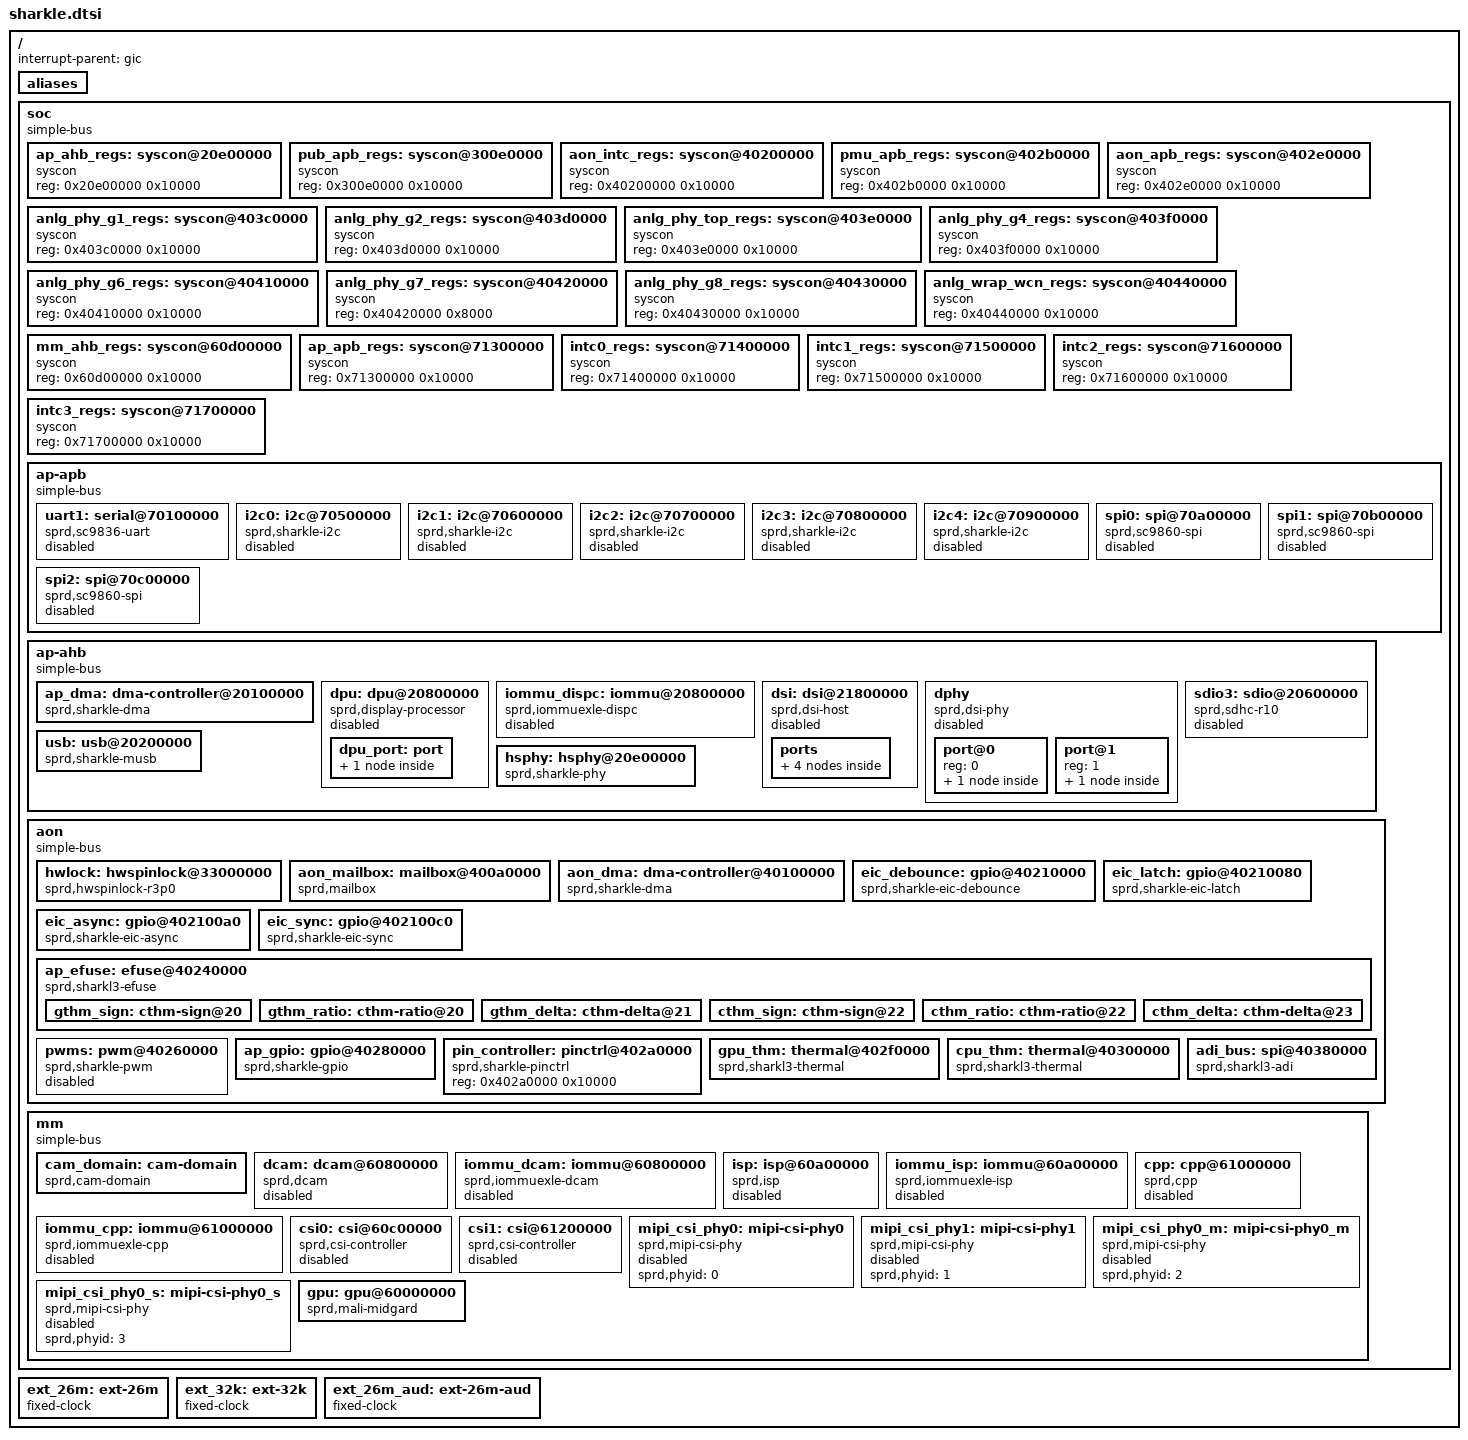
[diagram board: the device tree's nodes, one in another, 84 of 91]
/*
 * Spreadtrum sharkle platform DTS file
 *
 * Copyright (C) 2019, Spreadtrum Communications Inc.
 *
 * This file is licensed under a dual GPLv2 or X11 license.
 */
#include <dt-bindings/interrupt-controller/arm-gic.h>
#include <dt-bindings/soc/sprd,sharkle-regs.h>
#include <dt-bindings/soc/sprd,sharkle-mask.h>

/ {
	interrupt-parent = <&gic>;
	#address-cells = <1>;
	#size-cells = <1>;

	aliases {
		serial1 = &uart1;
		i2c0 = &i2c0;
		i2c1 = &i2c1;
		i2c2 = &i2c2;
		i2c3 = &i2c3;
		i2c4 = &i2c4;
		spi0 = &spi0;
		spi1 = &spi1;
		spi2 = &spi2;
	};

	soc: soc {
		compatible = "simple-bus";
		#address-cells = <1>;
		#size-cells = <1>;
		ranges;

		ap_ahb_regs: syscon@20e00000 {
			compatible = "syscon";
			#syscon-cells = <2>;
			reg = <0x20e00000 0x10000>;
		};

		pub_apb_regs: syscon@300e0000 {
			compatible = "syscon";
			#syscon-cells = <2>;
			reg = <0x300e0000 0x10000>;
		};

		aon_intc_regs: syscon@40200000 {
			compatible = "syscon";
			#syscon-cells = <2>;
			reg = <0x40200000 0x10000>;
		};

		pmu_apb_regs: syscon@402b0000 {
			compatible = "syscon";
			#syscon-cells = <2>;
			reg = <0x402b0000 0x10000>;
		};

		aon_apb_regs: syscon@402e0000 {
			compatible = "syscon";
			#syscon-cells = <2>;
			reg = <0x402e0000 0x10000>;
		};

		anlg_phy_g1_regs: syscon@403c0000 {
			compatible = "syscon";
			#syscon-cells = <2>;
			reg = <0x403c0000 0x10000>;
		};

		anlg_phy_g2_regs: syscon@403d0000 {
			compatible = "syscon";
			#syscon-cells = <2>;
			reg = <0x403d0000 0x10000>;
		};

		anlg_phy_top_regs: syscon@403e0000 {
			compatible = "syscon";
			#syscon-cells = <2>;
			reg = <0x403e0000 0x10000>;
		};

		anlg_phy_g4_regs: syscon@403f0000 {
			compatible = "syscon";
			#syscon-cells = <2>;
			reg = <0x403f0000 0x10000>;
		};

		anlg_phy_g6_regs: syscon@40410000 {
			compatible = "syscon";
			#syscon-cells = <2>;
			reg = <0x40410000 0x10000>;
		};

		anlg_phy_g7_regs: syscon@40420000 {
			compatible = "syscon";
			#syscon-cells = <2>;
			reg = <0x40420000 0x8000>;
		};

		anlg_phy_g8_regs: syscon@40430000 {
			compatible = "syscon";
			#syscon-cells = <2>;
			reg = <0x40430000 0x10000>;
		};

		anlg_wrap_wcn_regs: syscon@40440000 {
			compatible = "syscon";
			#syscon-cells = <2>;
			reg = <0x40440000 0x10000>;
		};

		mm_ahb_regs: syscon@60d00000 {
			compatible = "syscon";
			#syscon-cells = <2>;
			reg = <0x60d00000 0x10000>;
		};

		ap_apb_regs: syscon@71300000 {
			compatible = "syscon";
			#syscon-cells = <2>;
			reg = <0x71300000 0x10000>;
		};

		intc0_regs: syscon@71400000 {
			compatible = "syscon";
			#syscon-cells = <2>;
			reg = <0x71400000 0x10000>;
		};

		intc1_regs: syscon@71500000 {
			compatible = "syscon";
			#syscon-cells = <2>;
			reg = <0x71500000 0x10000>;
		};

		intc2_regs: syscon@71600000 {
			compatible = "syscon";
			#syscon-cells = <2>;
			reg = <0x71600000 0x10000>;
		};

		intc3_regs: syscon@71700000 {
			compatible = "syscon";
			#syscon-cells = <2>;
			reg = <0x71700000 0x10000>;
		};

		ap-apb {
			compatible = "simple-bus";
			#address-cells = <1>;
			#size-cells = <1>;
			ranges;

			uart1: serial@70100000 {
				compatible = "sprd,sc9836-uart";
				reg = <0x70100000 0x100>;
				interrupts = <GIC_SPI 3 IRQ_TYPE_LEVEL_HIGH>;
				status = "disabled";
			};

			i2c0: i2c@70500000 {
				compatible = "sprd,sharkle-i2c";
				reg = <0x70500000 0x100>;
				interrupts = <GIC_SPI 11 IRQ_TYPE_LEVEL_HIGH>;
				clock-frequency = <100000>;
				#address-cells = <1>;
				#size-cells = <0>;
				status = "disabled";
			};

			i2c1: i2c@70600000 {
				compatible = "sprd,sharkle-i2c";
				reg = <0x70600000 0x100>;
				interrupts = <GIC_SPI 12 IRQ_TYPE_LEVEL_HIGH>;
				clock-frequency = <100000>;
				#address-cells = <1>;
				#size-cells = <0>;
				status = "disabled";
			};

			i2c2: i2c@70700000 {
				compatible = "sprd,sharkle-i2c";
				reg = <0x70700000 0x100>;
				interrupts = <GIC_SPI 13 IRQ_TYPE_LEVEL_HIGH>;
				clock-frequency = <100000>;
				#address-cells = <1>;
				#size-cells = <0>;
				status = "disabled";
			};

			i2c3: i2c@70800000 {
				compatible = "sprd,sharkle-i2c";
				reg = <0x70800000 0x100>;
				interrupts = <GIC_SPI 14 IRQ_TYPE_LEVEL_HIGH>;
				clock-frequency = <400000>;
				#address-cells = <1>;
				#size-cells = <0>;
				status = "disabled";
			};

			i2c4: i2c@70900000 {
				compatible = "sprd,sharkle-i2c";
				reg = <0x70900000 0x100>;
				interrupts = <GIC_SPI 15 IRQ_TYPE_LEVEL_HIGH>;
				clock-frequency = <100000>;
				#address-cells = <1>;
				#size-cells = <0>;
				status = "disabled";
			};

			spi0: spi@70a00000 {
				compatible = "sprd,sc9860-spi",
					"sprd,sharkle-spi";
				reg = <0x70a00000 0x1000>;
				interrupts = <GIC_SPI 7 IRQ_TYPE_LEVEL_HIGH>;
				#address-cells = <1>;
				#size-cells = <0>;
				status = "disabled";
			};

			spi1: spi@70b00000 {
				compatible = "sprd,sc9860-spi",
					"sprd,sharkle-spi";
				reg = <0x70b00000 0x1000>;
				interrupts = <GIC_SPI 8 IRQ_TYPE_LEVEL_HIGH>;
				#address-cells = <1>;
				#size-cells = <0>;
				status = "disabled";
			};

			spi2: spi@70c00000 {
				compatible = "sprd,sc9860-spi",
					"sprd,sharkle-spi";
				reg = <0x70c00000 0x1000>;
				interrupts = <GIC_SPI 9 IRQ_TYPE_LEVEL_HIGH>;
				#address-cells = <1>;
				#size-cells = <0>;
				status = "disabled";
			};
		};

		ap-ahb {
			compatible = "simple-bus";
			#address-cells = <1>;
			#size-cells = <1>;
			ranges;

			ap_dma: dma-controller@20100000 {
				compatible = "sprd,sharkle-dma";
				reg = <0x20100000 0x4000>;
				interrupts = <GIC_SPI 50 IRQ_TYPE_LEVEL_HIGH>;
				#dma-cells = <1>;
				#dma-channels = <28>;
				clock-names = "enable";
				clocks = <&apahb_gate DMA_PUB_EB>;

			};


			dpu: dpu@20800000 {
				compatible = "sprd,display-processor";
				reg = <0x20800000 0x1000>;
				syscons = <&ap_ahb_regs REG_AP_AHB_AHB_RST
					MASK_AP_AHB_DISPC_SOFT_RST>;
				syscon-names = "reset";
				interrupts = <GIC_SPI 46 IRQ_TYPE_LEVEL_HIGH>;
				status = "disabled";
				iommus = <&iommu_dispc>;

				dma-coherent;

				sprd,ip = "dpu-lite-r1p0";
				sprd,soc = "sharkle";

				dpu_port: port {
					dpu_out: endpoint {
						remote-endpoint = <&dsi_in>;
					};
				};
			};

			iommu_dispc: iommu@20800000 {
				compatible = "sprd,iommuexle-dispc";
				reg = <0x20800000 0x800>,
				      <0x20800800 0x80>;
				iova-base = <0x70000000>;
				iova-size = <0x08000000>;
				reg_name = "mmu_interrupt_reg","mmu_reg";
				status = "disabled";
				#iommu-cells = <0>;
			};

			dsi: dsi@21800000 {
				compatible = "sprd,dsi-host";
				reg = <0x21800000 0x1000>;
				syscons = <&ap_ahb_regs REG_AP_AHB_AHB_RST
					MASK_AP_AHB_DSI_SOFT_RST>;
				syscon-names = "reset";
				interrupts = <GIC_SPI 48 IRQ_TYPE_LEVEL_HIGH>,
					<GIC_SPI 49 IRQ_TYPE_LEVEL_HIGH>;
				status = "disabled";

				sprd,ip = "sprd,dsi-ctrl", "r1p0";
				sprd,soc = "sharkle";

				ports {
					#address-cells = <1>;
					#size-cells = <0>;

					port@0 {
						reg = <0>;
						dsi_out: endpoint {
						  remote-endpoint = <&dphy_in>;
						};
					};

					port@1 {
						reg = <1>;
						dsi_in: endpoint {
						  remote-endpoint = <&dpu_out>;
						};
					};
				};
			};

			dphy: dphy {
				compatible = "sprd,dsi-phy";
				#address-cells = <1>;
				#size-cells = <0>;
				reg = <0x21800000 0x1000>;
				syscons = <&ap_ahb_regs
					REG_AP_AHB_MISC_CKG_EN
					(MASK_AP_AHB_DPHY_REF_CKG_EN |
					MASK_AP_AHB_DPHY_CFG_CKG_EN)>,
					<&pmu_apb_regs
					REG_PMU_APB_ANALOG_PHY_PD_CFG
					MASK_PMU_APB_DSI_PD_REG>;
				syscon-names = "enable", "power";
				status = "disabled";

				sprd,ip = "sprd,megacores-sharkle";
				sprd,soc = "sharkle";

				/* output port */
				port@0 {
					reg = <0>;
					dphy_out: endpoint {
						remote-endpoint = <&panel_in>;
					};
				};

				/* input port*/
				port@1 {
					reg = <1>;
					dphy_in: endpoint {
						remote-endpoint = <&dsi_out>;
					};
				};
			};

			sdio3: sdio@20600000 {
				compatible  = "sprd,sdhc-r10";
				reg = <0x20600000 0x1000>;
				interrupts = <GIC_SPI 60 IRQ_TYPE_LEVEL_HIGH>;
				clock-names = "sdio_clk","sdio_clk_source",
					"sdio_ahb_enable";
				clocks = <&ap_clk CLK_EMMC_2X >,
					 <&rpll CLK_RPLL_390M>,
					 <&apahb_gate EMMC_EB>;
				status = "disabled";
			};

			usb: usb@20200000 {
				compatible  = "sprd,sharkle-musb";
				reg = <0x20200000 0x2000>;
				interrupts = <GIC_SPI 55 IRQ_TYPE_LEVEL_HIGH>;
				interrupt-names = "mc";
				clocks = <&apahb_gate OTG_EB>;
				clock-names = "core_clk";
				usb-phy = <&hsphy>;
				phy-names = "usb";
			};

			hsphy: hsphy@20e00000 {
				compatible = "sprd,sharkle-phy";
				reg = <0x20e00000 0x3030>;
				reg-names = "phy_glb_regs";
				sprd,syscon-enable = <&aon_apb_regs>;
				sprd,tune-value = <0x0005af33>;
				sprd,vdd-voltage = <3300000>;
				#phy-cells = <0>;
			};
		};

		aon {
			compatible = "simple-bus";
			#address-cells = <1>;
			#size-cells = <1>;
			ranges;

			hwlock: hwspinlock@33000000{
				compatible = "sprd,hwspinlock-r3p0";
				reg = <0x33000000 0x10000>;
				#hwlock-cells = <1>;
				clock-names = "enable";
				clocks = <&aonapb_gate CLK_SPLK_EB>;
			};

			aon_mailbox: mailbox@400a0000 {
				compatible = "sprd,mailbox";
				reg = <0x400a0000 0x8000>,
				      <0x400a8000 0x8000>;
				syscons = <&aon_apb_regs 0x4 0x200000>;
				syscon-names = "clk";
				interrupts = <GIC_SPI 68 IRQ_TYPE_LEVEL_HIGH>,
					     <GIC_SPI 69 IRQ_TYPE_LEVEL_HIGH>;
				sprd,core-cnt = <7>;
				sprd,version = <0x102>;
			};

			aon_dma: dma-controller@40100000 {
				compatible = "sprd,sharkle-dma";
				reg = <0x40100000 0x4000>;
				#dma-cells = <1>;
				#dma-channels = <8>;
				clock-names = "enable";
				clocks = <&aonapb_gate CLK_AON_DMA_EB>;
			};

			eic_debounce: gpio@40210000 {
				compatible = "sprd,sharkle-eic-debounce";
				reg = <0x40210000 0x80>,
				      <0x40370000 0x80>,
				      <0x402c0000 0x80>;
				gpio-controller;
				#gpio-cells = <2>;
				interrupt-controller;
				#interrupt-cells = <2>;
				interrupts = <GIC_SPI 37 IRQ_TYPE_LEVEL_HIGH>;
			};

			eic_latch: gpio@40210080 {
				compatible = "sprd,sharkle-eic-latch";
				reg = <0x40210080 0x20>,
				      <0x40370080 0x20>,
				      <0x402c0080 0x20>;
				gpio-controller;
				#gpio-cells = <2>;
				interrupt-controller;
				#interrupt-cells = <2>;
				interrupts = <GIC_SPI 37 IRQ_TYPE_LEVEL_HIGH>;
			};

			eic_async: gpio@402100a0 {
				compatible = "sprd,sharkle-eic-async";
				reg = <0x402100a0 0x20>,
				      <0x403700a0 0x20>,
				      <0x402c00a0 0x20>;
				gpio-controller;
				#gpio-cells = <2>;
				interrupt-controller;
				#interrupt-cells = <2>;
				interrupts = <GIC_SPI 37 IRQ_TYPE_LEVEL_HIGH>;
			};

			eic_sync: gpio@402100c0 {
				compatible = "sprd,sharkle-eic-sync";
				reg = <0x402100c0 0x20>,
				      <0x403700c0 0x20>,
				      <0x402c00c0 0x20>;
				gpio-controller;
				#gpio-cells = <2>;
				interrupt-controller;
				#interrupt-cells = <2>;
				interrupts = <GIC_SPI 37 IRQ_TYPE_LEVEL_HIGH>;
			};

			ap_efuse: efuse@40240000 {
				compatible = "sprd,sharkl3-efuse", "sprd,sharkle-efuse";
				reg = <0x40240000 0x10000>;
				clock-names = "enable";
				hwlocks = <&hwlock 8>;
				clocks = <&aonapb_gate CLK_EFUSE_EB>;

				gthm_sign: cthm-sign@20{
					reg = <0x20 0x4>;
					bits = <1 1>;
				};

				gthm_ratio: cthm-ratio@20{
					reg = <0x20 0x4>;
					bits = <2 7>;
				};

				gthm_delta: cthm-delta@21{
					reg = <0x21 0x4>;
					bits = <1 7>;
				};

				cthm_sign: cthm-sign@22{
					reg = <0x22 0x4>;
					bits = <0 1>;
				};

				cthm_ratio: cthm-ratio@22{
					reg = <0x22 0x4>;
					bits = <1 7>;
				};

				cthm_delta: cthm-delta@23{
					reg = <0x23 0x4>;
					bits = <0 7>;
				};
			};

			pwms: pwm@40260000 {
				compatible = "sprd,sharkle-pwm", "sprd,sharkl5-pwm";
				reg = <0x40260000 0x10000>;
				clock-names = "clk_parent",
					"clk_pwm0", "clk_pwm0_eb",
					"clk_pwm1", "clk_pwm1_eb",
					"clk_pwm2", "clk_pwm2_eb",
					"clk_pwm3", "clk_pwm3_eb";
				clocks = <&ext_26m>,
					<&aon_prediv CLK_PWM0>,
					<&aonapb_gate CLK_PWM0_EB>,
					<&aon_prediv CLK_PWM1>,
					<&aonapb_gate CLK_PWM1_EB>,
					<&aon_prediv CLK_PWM2>,
					<&aonapb_gate CLK_PWM2_EB>,
					<&aon_prediv CLK_PWM3>,
					<&aonapb_gate CLK_PWM3_EB>;
				#pwm-cells = <2>;
				status = "disabled";
			};

			ap_gpio: gpio@40280000 {
				compatible = "sprd,sharkle-gpio";
				reg = <0x40280000 0x1000>;
				gpio-controller;
				#gpio-cells = <2>;
				interrupt-controller;
				#interrupt-cells = <2>;
				interrupts = <GIC_SPI 35 IRQ_TYPE_LEVEL_HIGH>;
			};

			pin_controller: pinctrl@402a0000 {
				compatible = "sprd,sharkle-pinctrl";
				reg = <0x402a0000 0x10000>;
			};

			gpu_thm: thermal@402f0000 {
				compatible = "sprd,sharkl3-thermal", "sprd,sharkle-thermal";
				reg = <0x402f0000 0x100>;
				clock-names = "enable";
				clocks = <&aonapb_gate CLK_THM0_EB>;
				#thermal-sensor-cells = <1>;
				nvmem-cells = <&gthm_sign>, <&gthm_ratio>, <&gthm_delta>;
				nvmem-cell-names = "thm_sign_cal", "thm_ratio_cal", "thm_delta_cal";
			};

			cpu_thm: thermal@40300000 {
				compatible = "sprd,sharkl3-thermal", "sprd,sharkle-thermal";
				reg = <0x40300000 0x100>;
				clock-names = "enable";
				clocks = <&aonapb_gate CLK_THM1_EB>;
				#thermal-sensor-cells = <1>;
				nvmem-cells = <&cthm_sign>, <&cthm_ratio>, <&cthm_delta>;
				nvmem-cell-names = "thm_sign_cal", "thm_ratio_cal", "thm_delta_cal";
			};

			adi_bus: spi@40380000 {
				compatible = "sprd,sharkl3-adi",
					"sprd,sharkle-adi";
				reg = <0x40380000 0x10000>;
				hwlocks = <&hwlock 0>;
				#address-cells = <1>;
				#size-cells = <0>;
			};
		};

		mm {
			compatible = "simple-bus";
			#address-cells = <1>;
			#size-cells = <1>;
			ranges;

			cam_domain: cam-domain {
				compatible = "sprd,cam-domain";
				syscons = <&pmu_apb_regs REG_PMU_APB_PD_MM_TOP_CFG MASK_PMU_APB_PD_MM_TOP_AUTO_SHUTDOWN_EN>,
					<&pmu_apb_regs REG_PMU_APB_PD_MM_TOP_CFG MASK_PMU_APB_PD_MM_TOP_FORCE_SHUTDOWN>,
					<&pmu_apb_regs REG_PMU_APB_PWR_STATUS3_DBG MASK_PMU_APB_PD_MM_TOP_STATE>,
					<&aon_apb_regs REG_AON_APB_APB_EB2 MASK_AON_APB_ANLG_APB_EB>,
					<&mm_ahb_regs REG_MM_AHB_QOS_THREHOLD_MM
					(MASK_MM_AHB_AR_QOS_THREHOLD_MM |
					MASK_MM_AHB_AW_QOS_THREHOLD_MM)>;
				syscon-names = "shutdown_en",
					"force_shutdown",
					"pd_mm_state",
					"anlg_apb_eb",
					"qos_threshold_mm";
			};

			dcam: dcam@60800000 {
				compatible = "sprd,dcam";
				reg = <0x60800000 0x1000>,
					<0x60801000 0x1000>,
					<0x60802000 0x1000>,
					<0x60803000 0x1000>,
					<0x60804000 0x4000>,
					<0x60808000 0x4000>;
				interrupts = <GIC_SPI 45 IRQ_TYPE_LEVEL_HIGH>,
					<GIC_SPI 66 IRQ_TYPE_LEVEL_HIGH>;
				sprd,cam-ahb-syscon = <&mm_ahb_regs>;
				sprd,isp = <&isp>;
				sprd,dcam-count = <2>;
				iommus = <&iommu_dcam>;
				status = "disabled";
			};

			iommu_dcam: iommu@60800000 {
				compatible = "sprd,iommuexle-dcam";
				reg = <0x60800000 0x2100>,
					<0x60802100 0x60>;
				iova-base = <0x40000000>;
				iova-size = <0x10000000>;
				reg_name = "mmu_interrupt_reg","mmu_reg",
					"iova pool";
				status = "disabled";
				#iommu-cells = <0>;
			};

			isp: isp@60a00000 {
				compatible = "sprd,isp";
				reg = <0x60a00000 0x100000>;
				interrupts = <GIC_SPI 44 IRQ_TYPE_LEVEL_HIGH>,
					<GIC_SPI 125 IRQ_TYPE_LEVEL_HIGH>;
				syscons = <&mm_ahb_regs REG_MM_AHB_AHB_RST MASK_MM_AHB_ISP_FMCU_SOFT_RST>,
					<&mm_ahb_regs REG_MM_AHB_AHB_RST
					(MASK_MM_AHB_ISP_LOG_SOFT_RST |
					MASK_MM_AHB_ISP_CFG_SOFT_RST |
					MASK_MM_AHB_ISP_FMCU_SOFT_RST)>;
				syscon-names = "fmcu_rst",
					"hw_rst";
				sprd,isp-count = <1>;
				iommus = <&iommu_isp>;
				status = "disabled";
			};

			iommu_isp: iommu@60a00000 {
				compatible = "sprd,iommuexle-isp";
				/* sharkle isp need pagetable size */
				reg = <0x60a00000 0x800>,
					<0x60a00800 0x400>;
				iova-base = <0x50000000>;
				iova-size = <0x10000000>;
				reg_name = "mmu_interrupt_reg","mmu_reg",
					"iova pool";
				status = "disabled";
				#iommu-cells = <0>;
			};

			cpp: cpp@61000000 {
				compatible = "sprd,cpp";
				reg = <0x61000000 0x1000>;
				interrupts = <GIC_SPI 27 IRQ_TYPE_LEVEL_HIGH>;
				syscons = <&mm_ahb_regs REG_MM_AHB_AHB_RST MASK_MM_AHB_CPP_SOFT_RST_MASK>;
				syscon-names = "cpp_rst";
				iommus = <&iommu_cpp>;
				status = "disabled";
			};

			iommu_cpp: iommu@61000000 {
				compatible = "sprd,iommuexle-cpp";
				reg = <0x61000000 0x200>,
					<0x61000200 0x60>;
				iova-base = <0x60000000>;
				iova-size = <0x8000000>;
				reg_name = "mmu_interrupt_reg","mmu_reg",
					"iova pool";
				status = "disabled";
				#iommu-cells = <0>;
			};

			csi0: csi@60c00000 {
				compatible = "sprd,csi-controller";
				reg = <0x60c00000 0x1000>;
				interrupts = <GIC_SPI 40 IRQ_TYPE_LEVEL_HIGH>,
					<GIC_SPI 41 IRQ_TYPE_LEVEL_HIGH>;
				sprd,cam-ahb-syscon = <&mm_ahb_regs>;
				sprd,ana-apb-syscon = <&aon_apb_regs>;
				sprd,anlg_phy_g7_controller = <&anlg_phy_g7_regs>;
				sprd,csi-id = <0>;
				sprd,dcam-id = <0>;
				sprd,ip-version = <0x200>;
				status = "disabled";
			};

			csi1: csi@61200000 {
				compatible = "sprd,csi-controller";
				reg = <0x61200000 0x1000>;
				interrupts = <GIC_SPI 71 IRQ_TYPE_LEVEL_HIGH>,
					<GIC_SPI 72 IRQ_TYPE_LEVEL_HIGH>;
				sprd,cam-ahb-syscon = <&mm_ahb_regs>;
				sprd,ana-apb-syscon = <&aon_apb_regs>;
				sprd,anlg_phy_g7_controller = <&anlg_phy_g7_regs>;
				sprd,csi-id = <1>;
				sprd,dcam-id = <1>;
				sprd,ip-version = <0x200>;
				status = "disabled";
			};

			/* phy0 is 2p2lane phy */
			mipi_csi_phy0: mipi-csi-phy0 {
				compatible = "sprd,mipi-csi-phy";
				sprd,phyid = <0>;
				status = "disabled";
			};

			/* phy0 is 4lane phy */
			mipi_csi_phy1: mipi-csi-phy1 {
				compatible = "sprd,mipi-csi-phy";
				sprd,phyid = <1>;
				status = "disabled";
			};

			/* phy0 is 2p2lane phy master */
			mipi_csi_phy0_m: mipi-csi-phy0_m {
				compatible = "sprd,mipi-csi-phy";
				sprd,phyid = <2>;
				status = "disabled";
			};

			/* phy0 is 2p2lane phy slaver */
			mipi_csi_phy0_s: mipi-csi-phy0_s {
				compatible = "sprd,mipi-csi-phy";
				sprd,phyid = <3>;
				status = "disabled";
			};

			gpu: gpu@60000000 {
				compatible = "sprd,mali-midgard";
				reg = <0x60000000 0x4000>;
				gpu-supply = <&vddcore>;
				syscons = <&pmu_apb_regs
					REG_PMU_APB_PD_GPU_TOP_CFG
					MASK_PMU_APB_PD_GPU_TOP_FORCE_SHUTDOWN>;
				syscon-names = "top_force_shutdown";

				interrupts = <GIC_SPI 39 IRQ_TYPE_LEVEL_HIGH>,
					<GIC_SPI 39 IRQ_TYPE_LEVEL_HIGH>,
					<GIC_SPI 39 IRQ_TYPE_LEVEL_HIGH>;
				interrupt-names = "JOB",
					"MMU",
					"GPU";

				operating-points = <
					/* kHz    uV */
					256000    900000
					384000    900000
					512000    900000
					600000    900000
					680000    900000
					>;

				sprd,dfs-lists = <
					/* kHz  uV      idx div */
					256000  900000   2    1
					384000  900000   4    1
					512000  900000   5    1
					600000  900000   6    1
					680000  900000   6    1
					>;

				sprd,dfs-default = <1>;
				sprd,dfs-scene-extreme = <3>;
				sprd,dfs-scene-high = <2>;
				sprd,dfs-scene-medium = <1>;
				sprd,dfs-scene-low = <0>;
				sprd,dfs-range-max = <3>;
				sprd,dfs-range-min = <0>;
			};
		};
	};

	ext_26m: ext-26m {
		compatible = "fixed-clock";
		#clock-cells = <0>;
		clock-frequency = <26000000>;
		clock-output-names = "ext-26m";
	};

	ext_32k: ext-32k {
		compatible = "fixed-clock";
		#clock-cells = <0>;
		clock-frequency = <32768>;
		clock-output-names = "ext-32k";
	};

	ext_26m_aud: ext-26m-aud {
		compatible = "fixed-clock";
		#clock-cells = <0>;
		clock-frequency = <26000000>;
		clock-output-names = "ext-26m-aud";
	};

};
